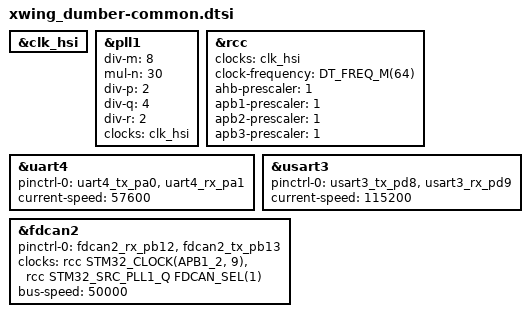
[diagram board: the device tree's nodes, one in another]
/*
 * Copyright (c) 2021 Linaro Limited
 * Copyright (c) 2023 Thomas Stranger
 *
 * SPDX-License-Identifier: Apache-2.0
 */

#include <st/h5/stm32h563Xi.dtsi>
#include <st/h5/stm32h563zitx-pinctrl.dtsi>

&clk_hsi {
	status = "okay";
};

/* PLL1 is used only to supply PLL1_Q as the FDCAN kernel clock.
 * System clock stays on HSI directly.
 * HSI=64MHz, /M=8 -> ref=8MHz, *N=30 -> VCO=240MHz, /Q=4 -> PLL1_Q=60MHz */
&pll1 {
	div-m = <8>;
	mul-n = <30>;
	div-p = <2>;
	div-q = <4>;
	div-r = <2>;
	clocks = <&clk_hsi>;
	status = "okay";
};

&rcc {
	clocks = <&clk_hsi>;
	clock-frequency = <DT_FREQ_M(64)>;
	ahb-prescaler = <1>;
	apb1-prescaler = <1>;
	apb2-prescaler = <1>;
	apb3-prescaler = <1>;
};

&uart4 {
	pinctrl-0 = <&uart4_tx_pa0 &uart4_rx_pa1>;
	pinctrl-names = "default";
	current-speed = <57600>;
	status = "okay";
};

&usart3 {
    pinctrl-0 = <&usart3_tx_pd8 &usart3_rx_pd9>;
    pinctrl-names = "default";
    current-speed = <115200>;
    status = "okay";
};

&fdcan2 {
	pinctrl-0 = <&fdcan2_rx_pb12 &fdcan2_tx_pb13>;
	pinctrl-names = "default";
	clocks = <&rcc STM32_CLOCK(APB1_2, 9)>,
		 <&rcc STM32_SRC_PLL1_Q FDCAN_SEL(1)>;
	status = "okay";
	bus-speed = <50000>;
};

